# AT32F403 register map
Vendor: Keil; Series: AT32F403; File version: 1.0
CPU: CM4 r0p1, little endian, no MPU, FPU, 4 interrupt priority bits
Registers are 32-bit, read-write, reset 0x0 unless marked. A register's access mark holds for its fields unless they carry their own. Offsets are from the block's base; [hi:lo] are bit positions; {n}, {i} and the like mark numbered series; 'fields as' and 'values as' point back to an identical list.

## DAC — Digital to analog converter
Base 0x40007400
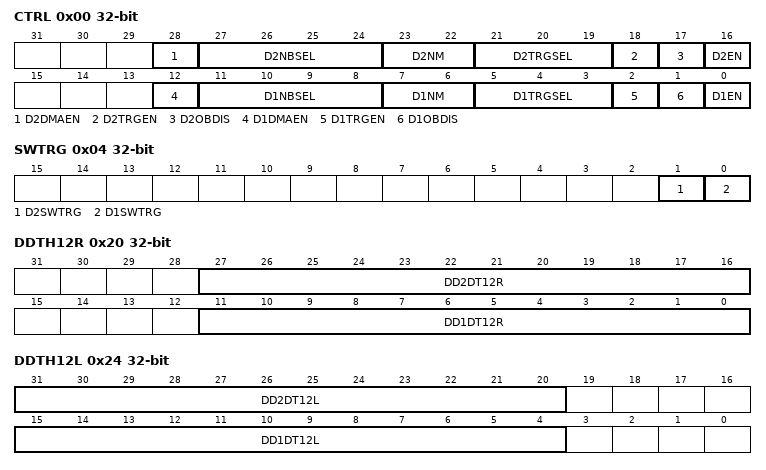
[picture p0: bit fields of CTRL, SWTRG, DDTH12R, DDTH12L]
0x00 CTRL — Control register (DAC_CTRL)
  [28] D2DMAEN — DAC2 DMA enable
  [27:24] D2NBSEL — DAC2 mask/amplitude selector
  [23:22] D2NM — DAC2 noise/triangle wave generation enable
  [21:19] D2TRGSEL — DAC2 trigger selection
  [18] D2TRGEN — DAC2 trigger enable
  [17] D2OBDIS — DAC2 output buffer disable
  [16] D2EN — DAC2 enable
  [12] D1DMAEN — DAC1 DMA enable
  [11:8] D1NBSEL — DAC1 mask/amplitude selector
  [7:6] D1NM — DAC1 noise/triangle wave generation enable
  [5:3] D1TRGSEL — DAC1 trigger selection
  [2] D1TRGEN — DAC1 trigger enable
  [1] D1OBDIS — DAC1 output buffer disable
  [0] D1EN — DAC1 enable
0x04 SWTRG — DAC software trigger register(DAC_SWTRIGR)
  [1] D2SWTRG — DAC2 software trigger
  [0] D1SWTRG — DAC1 software trigger
0x08 D1DTH12R — DAC1 12-bit right-aligned data holding register(DAC_D1DTH12R)
  [11:0] D1DT12R — DAC1 12-bit right-aligned data
0x0C D1DTH12L — DAC1 12-bit left aligned data holding register (DAC_D1DTH12L)
  [15:4] D1DT12L — DAC1 12-bit left-aligned data
0x10 D1DTH8R — DAC1 8-bit right aligned data holding register (DAC_D1DTH8R)
  [7:0] D1DT8R — DAC1 8-bit right-aligned data
0x14 D2DTH12R — DAC2 12-bit right aligned data holding register (DAC_D2DTH12R)
  [11:0] D2DT12R — DAC2 12-bit right-aligned data
0x18 D2DTH12L — DAC2 12-bit left aligned data holding register (DAC_D2DTH12L)
  [15:4] D2DT12L — DAC2 12-bit left-aligned data
0x1C D2DTH8R — DAC2 8-bit right-aligned data holding register (DAC_D2DTH8R)
  [7:0] D2DT8R — DAC2 8-bit right-aligned data
0x20 DDTH12R — Dual DAC 12-bit right-aligned data holding register (DAC_DDTH12R), Bits 31:28 Reserved, Bits 15:12 Reserved
  [27:16] DD2DT12R — DAC2 12-bit right-aligned data
  [11:0] DD1DT12R — DAC1 12-bit right-aligned data
0x24 DDTH12L — DUAL DAC 12-bit left aligned data holding register (DAC_DDTH12L), Bits 19:16 Reserved, Bits 3:0 Reserved
  [31:20] DD2DT12L — DAC2 12-bit right-aligned data
  [15:4] DD1DT12L — DAC1 12-bit left-aligned data
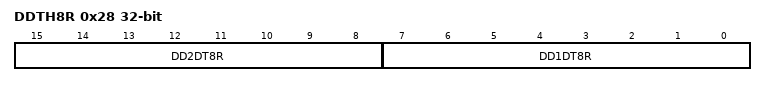
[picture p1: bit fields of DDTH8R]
0x28 DDTH8R — DUAL DAC 8-bit right aligned data holding register (DAC_DDTH8R), Bits 31:16 Reserved
  [15:8] DD2DT8R — DAC2 8-bit right-aligned data
  [7:0] DD1DT8R — DAC1 8-bit right-aligned data
0x2C D1ODT ro — DAC1 data output register (DAC_D1ODT)
  [11:0] D1ODT — DAC1 data output
0x30 D2ODT ro — DAC2 data output register (DAC_D2ODT)
  [11:0] D2ODT — DAC2 data output

## DEBUG — Debug support
Base 0xE0042000
0x00 IDCODE ro — DEBUG_IDCODE
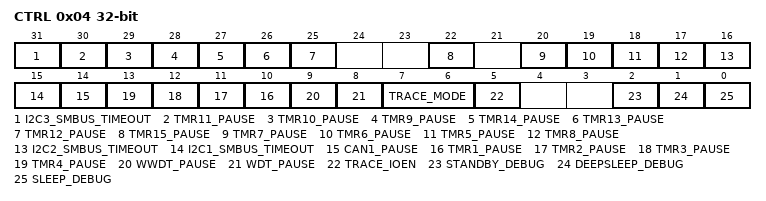
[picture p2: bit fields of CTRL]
0x04 CTRL — DEBUG_CTRL
  [31] I2C3_SMBUS_TIMEOUT
  [30] TMR11_PAUSE — Timer pause control bit
    0=Continue (The counter clock of TMRx is fed even if the core is halted); 1=Pause (The counter clock of TMRx is stopped when the core is halted)
  [29] TMR10_PAUSE — Timer pause control bit
    values as TMR11_PAUSE
  [28] TMR9_PAUSE — Timer pause control bit
    values as TMR11_PAUSE
  [27] TMR14_PAUSE — Timer pause control bit
    values as TMR11_PAUSE
  [26] TMR13_PAUSE — Timer pause control bit
    values as TMR11_PAUSE
  [25] TMR12_PAUSE — Timer pause control bit
    values as TMR11_PAUSE
  [22] TMR15_PAUSE — Timer pause control bit
    values as TMR11_PAUSE
  [20] TMR7_PAUSE — Timer pause control bit
    values as TMR11_PAUSE
  [19] TMR6_PAUSE — Timer pause control bit
    values as TMR11_PAUSE
  [18] TMR5_PAUSE — Timer pause control bit
    values as TMR11_PAUSE
  [17] TMR8_PAUSE — Timer pause control bit
    values as TMR11_PAUSE
  [16] I2C2_SMBUS_TIMEOUT
  [15] I2C1_SMBUS_TIMEOUT
  [14] CAN1_PAUSE
  [n+9] TMR{n}_PAUSE (n=1..4) — Timer pause control bit
    values as TMR11_PAUSE
  [9] WWDT_PAUSE
    values as TMR11_PAUSE
  [8] WDT_PAUSE
    values as TMR11_PAUSE
  [7:6] TRACE_MODE
  [5] TRACE_IOEN
  [2] STANDBY_DEBUG — Debug Standby mode control bit
    on read: 0=Disabled (The whole 1.2V digital circuit is unpowered in Standby mode); 1=Enabled (The whole 1.2V digital circuit is not unpowered in Standby mode, and the system clock is provided by the internal RC oscillator (HICK)) | on write: 0=Disable (The whole 1.2V digital circuit is unpowered in Standby mode); 1=Enable (The whole 1.2V digital circuit is not unpowered in Standby mode, and the system clock is provided by the internal RC oscillator (HICK))
  [1] DEEPSLEEP_DEBUG — Debug Deepsleep mode control bit
    on read: 0=Disabled (In Deepsleep mode, all clocks in the 1.2V domain are disabled); 1=Enabled (In Deepsleep mode, system clock is provided by the internal RC oscillator (HICK)) | on write: 0=Disable (In Deepsleep mode, all clocks in the 1.2V domain are disabled); 1=Enable (In Deepsleep mode, system clock is provided by the internal RC oscillator (HICK))
  [0] SLEEP_DEBUG — Debug Sleep mode control bit
    on read: 0=Disabled (When entering Sleep mode, CPU HCLK clock is disabled, but other clocks remain active); 1=Enabled (When entering Sleep mode, all clocks keep running) | on write: 0=Disable (When entering Sleep mode, CPU HCLK clock is disabled, but other clocks remain active); 1=Enable (When entering Sleep mode, all clocks keep running)

## CRC — CRC calculation unit
Base 0x40023000
0x00 DT reset 0xFFFFFFFF — Data register
0x04 CDT — Common data register
  [7:0] CDT — Common Data
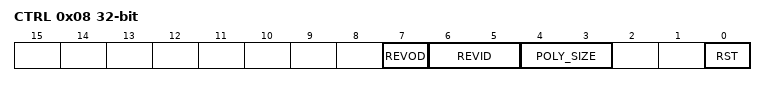
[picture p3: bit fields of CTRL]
0x08 CTRL — Control register
  [7] REVOD — Reverse output data
    0=NoEffect; 1=WordReverse
  [6:5] REVID — Reverse input data
    0=NoEffect; 1=ByteReverse; 2=HalfWordReverse; 3=WordReverse
  [4:3] POLY_SIZE — Polynomial size
    0=bits32 (32 bits); 1=bits16 (16 bits); 2=bits8 (8 bits); 3=bits7 (7 bits)
  [0] RST write-1-sets — Reset bit
    on write: 1=Reset CRC calculation unit, the data register is set as 0xFFFF FFFF
0x10 IDT reset 0xFFFFFFFF — Initial data register
0x14 POLY reset 0x4C11DB7 — Polynomial coefficient register

## NVIC — Nested Vectored Interrupt Controller
Base 0xE000E000
0x04 ICTR ro — Interrupt Controller Type Register
  [3:0] INTLINESNUM — Total number of interrupt lines in groups
0x100 ISER0 — Interrupt Set-Enable Register
  [31:0] SETENA
0x104 ISER1 — Interrupt Set-Enable Register
  [31:0] SETENA
0x180 ICER0 — Interrupt Clear-Enable Register
  [31:0] CLRENA
0x184 ICER1 — Interrupt Clear-Enable Register
  [31:0] CLRENA
0x200 ISPR0 — Interrupt Set-Pending Register
  [31:0] SETPEND
0x204 ISPR1 — Interrupt Set-Pending Register
  [31:0] SETPEND
0x280 ICPR0 — Interrupt Clear-Pending Register
  [31:0] CLRPEND
0x284 ICPR1 — Interrupt Clear-Pending Register
  [31:0] CLRPEND
0x300 IABR0 ro — Interrupt Active Bit Register
  [31:0] ACTIVE
0x304 IABR1 ro — Interrupt Active Bit Register
  [31:0] ACTIVE
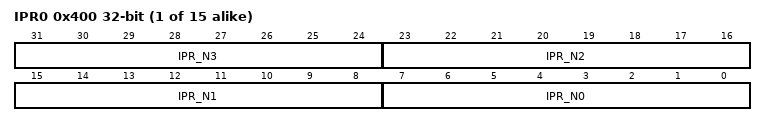
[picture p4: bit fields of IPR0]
{0x400+4i} IPR{i} (i=0..14) — Interrupt Priority Register
  [8n+7:8n] IPR_N{n} (n=0..3)
0xF00 STIR wo — Software Triggered Interrupt Register
  [8:0] INTID — interrupt to be triggered

## USBFS — Universal serial bus full-speed device interface
Base 0x40005C00
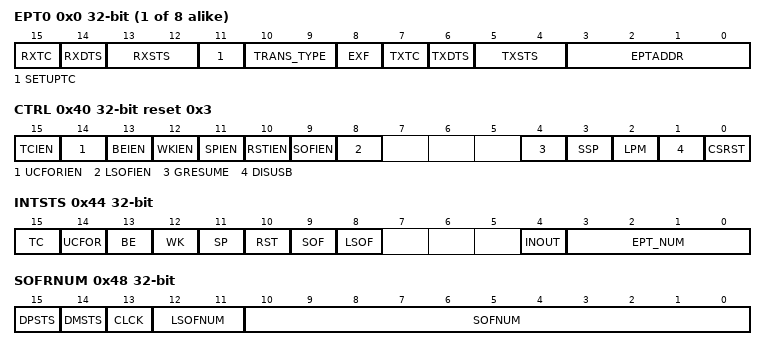
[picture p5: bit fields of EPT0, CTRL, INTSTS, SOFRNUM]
{0x0+4i} EPT{i} (i=0..7) — endpoint {i} register
  [15] RXTC — Rx transaction completed
  [14] RXDTS — Rx data toggle synchronization
  [13:12] RXSTS — Rx Status
  [11] SETUPTC — Setup transaction completed
  [10:9] TRANS_TYPE — Transfer type
  [8] EXF — Endpoint extend function
  [7] TXTC — Tx transaction completed
  [6] TXDTS — Tx data toggle synchronization
  [5:4] TXSTS — Tx status
  [3:0] EPTADDR — Endpoint address
0x40 CTRL reset 0x3 — control register
  [15] TCIEN — transmission completed interrupt enable
  [14] UCFORIEN — USB Core fifo overrun interrupt enable
  [13] BEIEN — Bus error interrupt enable
  [12] WKIEN — Wakeup/Remote wakeup interrupt enable
  [11] SPIEN — Bus suspend mode interrupt enable
  [10] RSTIEN — Bus reset interrupt enable
  [9] SOFIEN — Start of frame interrupt enable
  [8] LSOFIEN — Lost start of frame interrupt enable
  [4] GRESUME — Generate resume request
  [3] SSP — Soft suspend config
  [2] LPM — Low power mode
  [1] DISUSB — Disable usb phy
  [0] CSRST — Core soft reset
0x44 INTSTS — interrupt status register
  [15] TC — transaction completed
  [14] UCFOR — USB core fifo overrun memory
  [13] BE — Bus error
  [12] WK — Wakeup
  [11] SP — Bus suspend
  [10] RST — Bus reset
  [9] SOF — start of frame
  [8] LSOF — Lost start of frame
  [4] INOUT — In/Out transaction
  [3:0] EPT_NUM — Endpoint number
0x48 SOFRNUM — frame number register
  [15] DPSTS — DP status
  [14] DMSTS — DM status
  [13] CLCK — Connect locked
  [12:11] LSOFNUM — Lost start of frame number
  [10:0] SOFNUM — Start of frame number
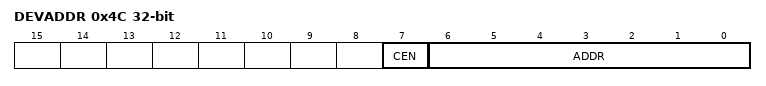
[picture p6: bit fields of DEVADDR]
0x4C DEVADDR — device address
  [7] CEN — USB core enable
  [6:0] ADDR — Host assign device address
0x50 BUFTBL — Buffer table address
  [15:3] BTADDR — Endpoint buffer table start address
